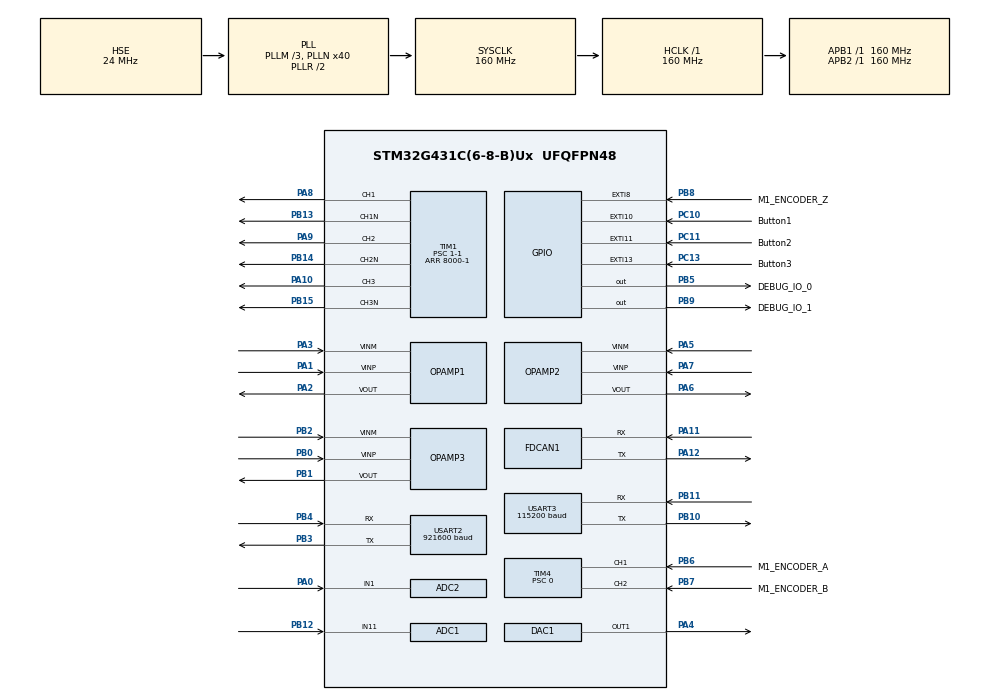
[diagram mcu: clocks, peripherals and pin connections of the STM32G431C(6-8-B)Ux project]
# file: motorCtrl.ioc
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ADC1.Channel-0\#ChannelRegularConversion=ADC_CHANNEL_11
ADC1.ClockPrescaler=ADC_CLOCK_ASYNC_DIV4
ADC1.EnableInjectedConversion=ENABLE
ADC1.ExternalTrigInjecConv=ADC_EXTERNALTRIGINJEC_T1_CC4
ADC1.InjNumberOfConversion=2
ADC1.InjectedChannel-3\#ChannelInjectedConversion=ADC_CHANNEL_3
ADC1.InjectedChannel-4\#ChannelInjectedConversion=ADC_CHANNEL_12
ADC1.InjectedOffsetNumber-3\#ChannelInjectedConversion=ADC_OFFSET_NONE
ADC1.InjectedOffsetNumber-4\#ChannelInjectedConversion=ADC_OFFSET_NONE
ADC1.InjectedRank-3\#ChannelInjectedConversion=1
ADC1.InjectedRank-4\#ChannelInjectedConversion=2
ADC1.InjectedSamplingTime-3\#ChannelInjectedConversion=ADC_SAMPLETIME_6CYCLES_5
ADC1.InjectedSamplingTime-4\#ChannelInjectedConversion=ADC_SAMPLETIME_6CYCLES_5
ADC1.NbrOfConversionFlag=1
ADC1.OffsetNumber-0\#ChannelRegularConversion=ADC_OFFSET_NONE
ADC1.Rank-0\#ChannelRegularConversion=1
ADC1.Rank1_Channel=ADC_CHANNEL_3
ADC1.Rank2_Channel=ADC_CHANNEL_12
ADC1.SamplingTime-0\#ChannelRegularConversion=ADC_SAMPLETIME_2CYCLES_5
ADC1.master=1
ADC2.Channel-2\#ChannelRegularConversion=ADC_CHANNEL_1
ADC2.ClockPrescaler=ADC_CLOCK_ASYNC_DIV4
ADC2.EnableInjectedConversion=ENABLE
ADC2.ExternalTrigInjecConv=ADC_EXTERNALTRIGINJEC_T1_CC4
ADC2.InjNumberOfConversion=1
ADC2.InjectedChannel-3\#ChannelInjectedConversion=ADC_CHANNEL_3
ADC2.InjectedOffsetNumber-3\#ChannelInjectedConversion=ADC_OFFSET_NONE
ADC2.InjectedRank-3\#ChannelInjectedConversion=1
ADC2.InjectedSamplingTime-3\#ChannelInjectedConversion=ADC_SAMPLETIME_6CYCLES_5
ADC2.NbrOfConversionFlag=1
ADC2.OffsetNumber-2\#ChannelRegularConversion=ADC_OFFSET_NONE
ADC2.Rank-2\#ChannelRegularConversion=1
ADC2.SamplingTime-2\#ChannelRegularConversion=ADC_SAMPLETIME_2CYCLES_5
COMP1.TriggerMode=COMP_TRIGGERMODE_IT_RISING
Dma.ADC1.2.Direction=DMA_PERIPH_TO_MEMORY
Dma.ADC1.2.EventEnable=DISABLE
Dma.ADC1.2.Instance=DMA1_Channel3
Dma.ADC1.2.MemDataAlignment=DMA_MDATAALIGN_HALFWORD
Dma.ADC1.2.MemInc=DMA_MINC_ENABLE
Dma.ADC1.2.Mode=DMA_NORMAL
Dma.ADC1.2.PeriphDataAlignment=DMA_PDATAALIGN_HALFWORD
Dma.ADC1.2.PeriphInc=DMA_PINC_DISABLE
Dma.ADC1.2.Polarity=HAL_DMAMUX_REQ_GEN_RISING
Dma.ADC1.2.Priority=DMA_PRIORITY_LOW
Dma.ADC1.2.RequestNumber=1
Dma.ADC1.2.SignalID=NONE
Dma.ADC1.2.SyncEnable=DISABLE
Dma.ADC1.2.SyncPolarity=HAL_DMAMUX_SYNC_NO_EVENT
Dma.ADC1.2.SyncRequestNumber=1
Dma.ADC1.2.SyncSignalID=NONE
Dma.ADC2.3.Direction=DMA_PERIPH_TO_MEMORY
Dma.ADC2.3.EventEnable=DISABLE
Dma.ADC2.3.Instance=DMA1_Channel4
Dma.ADC2.3.MemDataAlignment=DMA_MDATAALIGN_HALFWORD
Dma.ADC2.3.MemInc=DMA_MINC_ENABLE
Dma.ADC2.3.Mode=DMA_NORMAL
Dma.ADC2.3.PeriphDataAlignment=DMA_PDATAALIGN_HALFWORD
Dma.ADC2.3.PeriphInc=DMA_PINC_DISABLE
Dma.ADC2.3.Polarity=HAL_DMAMUX_REQ_GEN_RISING
Dma.ADC2.3.Priority=DMA_PRIORITY_LOW
Dma.ADC2.3.RequestNumber=1
Dma.ADC2.3.SignalID=NONE
Dma.ADC2.3.SyncEnable=DISABLE
Dma.ADC2.3.SyncPolarity=HAL_DMAMUX_SYNC_NO_EVENT
Dma.ADC2.3.SyncRequestNumber=1
Dma.ADC2.3.SyncSignalID=NONE
Dma.Request0=USART3_TX
Dma.Request1=USART2_TX
Dma.Request2=ADC1
Dma.Request3=ADC2
Dma.USART2_TX.1.Direction=DMA_MEMORY_TO_PERIPH
Dma.USART2_TX.1.EventEnable=DISABLE
Dma.USART2_TX.1.Instance=DMA1_Channel2
Dma.USART2_TX.1.MemDataAlignment=DMA_MDATAALIGN_BYTE
Dma.USART2_TX.1.MemInc=DMA_MINC_ENABLE
Dma.USART2_TX.1.Mode=DMA_NORMAL
Dma.USART2_TX.1.PeriphDataAlignment=DMA_PDATAALIGN_BYTE
Dma.USART2_TX.1.PeriphInc=DMA_PINC_DISABLE
Dma.USART2_TX.1.Polarity=HAL_DMAMUX_REQ_GEN_RISING
Dma.USART2_TX.1.Priority=DMA_PRIORITY_LOW
Dma.USART2_TX.1.RequestNumber=1
Dma.USART2_TX.1.SignalID=NONE
Dma.USART2_TX.1.SyncEnable=DISABLE
Dma.USART2_TX.1.SyncPolarity=HAL_DMAMUX_SYNC_NO_EVENT
Dma.USART2_TX.1.SyncRequestNumber=1
Dma.USART2_TX.1.SyncSignalID=NONE
Dma.USART3_TX.0.Direction=DMA_MEMORY_TO_PERIPH
Dma.USART3_TX.0.EventEnable=DISABLE
Dma.USART3_TX.0.Instance=DMA1_Channel1
Dma.USART3_TX.0.MemDataAlignment=DMA_MDATAALIGN_BYTE
Dma.USART3_TX.0.MemInc=DMA_MINC_ENABLE
Dma.USART3_TX.0.Mode=DMA_NORMAL
Dma.USART3_TX.0.PeriphDataAlignment=DMA_PDATAALIGN_BYTE
Dma.USART3_TX.0.PeriphInc=DMA_PINC_DISABLE
Dma.USART3_TX.0.Polarity=HAL_DMAMUX_REQ_GEN_RISING
Dma.USART3_TX.0.Priority=DMA_PRIORITY_LOW
Dma.USART3_TX.0.RequestNumber=1
Dma.USART3_TX.0.SignalID=NONE
Dma.USART3_TX.0.SyncEnable=DISABLE
Dma.USART3_TX.0.SyncPolarity=HAL_DMAMUX_SYNC_NO_EVENT
Dma.USART3_TX.0.SyncRequestNumber=1
Dma.USART3_TX.0.SyncSignalID=NONE
FDCAN1.DataPrescaler=20
FDCAN1.DataTimeSeg1=10
FDCAN1.DataTimeSeg2=5
FDCAN1.ExtFiltersNbr=1
FDCAN1.NominalPrescaler=20
FDCAN1.NominalTimeSeg1=10
FDCAN1.NominalTimeSeg2=5
FDCAN1.StdFiltersNbr=1
Mcu.Family=STM32G4
Mcu.Name=STM32G431C(6-8-B)Ux
Mcu.Package=UFQFPN48
NVIC.ADC1_2_IRQn=true\:0\:0\:false\:false\:true\:true\:true\:true
NVIC.COMP1_2_3_IRQn=true\:0\:0\:false\:false\:true\:false\:true\:true
NVIC.DMA1_Channel1_IRQn=true\:0\:0\:false\:false\:true\:false\:true\:true
NVIC.DMA1_Channel2_IRQn=true\:0\:0\:false\:false\:true\:false\:true\:true
NVIC.DMA1_Channel3_IRQn=true\:0\:0\:false\:false\:true\:false\:true\:true
NVIC.DMA1_Channel4_IRQn=true\:0\:0\:false\:false\:true\:false\:true\:true
NVIC.EXTI15_10_IRQn=true\:2\:0\:true\:false\:true\:true\:true\:true
NVIC.EXTI9_5_IRQn=true\:2\:0\:true\:false\:true\:true\:true\:true
NVIC.FDCAN1_IT0_IRQn=true\:4\:0\:true\:false\:true\:true\:true\:true
NVIC.PriorityGroup=NVIC_PRIORITYGROUP_4
NVIC.TIM1_BRK_TIM15_IRQn=true\:1\:0\:true\:false\:true\:true\:true\:true
NVIC.TIM1_CC_IRQn=true\:1\:0\:true\:false\:true\:true\:true\:true
NVIC.TIM1_UP_TIM16_IRQn=true\:1\:0\:true\:false\:true\:true\:true\:true
NVIC.TIM4_IRQn=true\:4\:0\:true\:false\:true\:true\:true\:true
NVIC.USART2_IRQn=true\:4\:0\:true\:false\:true\:true\:true\:true
NVIC.USART3_IRQn=true\:4\:0\:true\:false\:true\:true\:true\:true
PA0.Mode=IN1-Single-Ended
PA0.Signal=ADC2_IN1
PA1.Mode=Standalone
PA1.Signal=OPAMP1_VINP
PA10.Signal=S_TIM1_CH3
PA11.Mode=FDCAN_Activate
PA11.Signal=FDCAN1_RX
PA12.Mode=FDCAN_Activate
PA12.Signal=FDCAN1_TX
PA13.Mode=Serial_Wire
PA13.Signal=SYS_JTMS-SWDIO
PA14.Mode=Serial_Wire
PA14.Signal=SYS_JTCK-SWCLK
PA2.Signal=SharedAnalog_PA2
PA3.Mode=Standalone
PA3.Signal=OPAMP1_VINM
PA4.Signal=COMP_DAC11_group
PA5.Mode=Standalone
PA5.Signal=OPAMP2_VINM
PA6.Signal=SharedAnalog_PA6
PA7.Mode=Standalone
PA7.Signal=OPAMP2_VINP
PA8.Signal=S_TIM1_CH1
PA9.Signal=S_TIM1_CH2
PB0.Mode=Standalone
PB0.Signal=OPAMP3_VINP
PB1.Signal=SharedAnalog_PB1
PB10.Mode=Asynchronous
PB10.Signal=USART3_TX
PB11.Mode=Asynchronous
PB11.Signal=USART3_RX
PB12.Mode=IN11-Single-Ended
PB12.Signal=ADC1_IN11
PB13.Mode=PWM Generation1 CH1 CH1N
PB13.Signal=TIM1_CH1N
PB14.Mode=PWM Generation2 CH2 CH2N
PB14.Signal=TIM1_CH2N
PB15.Mode=PWM Generation3 CH3 CH3N
PB15.Signal=TIM1_CH3N
PB2.Mode=Standalone
PB2.Signal=OPAMP3_VINM
PB3.Mode=Asynchronous
PB3.Signal=USART2_TX
PB4.Mode=Asynchronous
PB4.Signal=USART2_RX
PB5.GPIO_Label=DEBUG_IO_0
PB5.Signal=GPIO_Output
PB6.GPIO_FM6=SYSCFG_FASTMODEPLUS_PB6
PB6.GPIO_Label=M1_ENCODER_A
PB6.Signal=S_TIM4_CH1
PB7.GPIO_FM7=SYSCFG_FASTMODEPLUS_PB7
PB7.GPIO_Label=M1_ENCODER_B
PB7.Signal=S_TIM4_CH2
PB8-BOOT0.GPIO_Label=M1_ENCODER_Z
PB8-BOOT0.Signal=GPXTI8
PB9.GPIO_Label=DEBUG_IO_1
PB9.Signal=GPIO_Output
PC10.GPIO_Label=Button1
PC10.Signal=GPXTI10
PC11.GPIO_Label=Button2
PC11.Signal=GPXTI11
PC13.GPIO_Label=Button3
PC13.Signal=GPXTI13
PF0-OSC_IN.Mode=HSE-External-Oscillator
PF0-OSC_IN.Signal=RCC_OSC_IN
PF1-OSC_OUT.Mode=HSE-External-Oscillator
PF1-OSC_OUT.Signal=RCC_OSC_OUT
ProjectManager.HeapSize=0x200
ProjectManager.StackSize=0x400
ProjectManager.TargetToolchain=STM32CubeIDE
RCC.ADC12Freq_Value=160000000
RCC.AHBFreq_Value=160000000
RCC.APB1Freq_Value=160000000
RCC.APB1TimFreq_Value=160000000
RCC.APB2Freq_Value=160000000
RCC.APB2TimFreq_Value=160000000
RCC.CortexFreq_Value=160000000
RCC.EXTERNAL_CLOCK_VALUE=12288000
RCC.HCLKFreq_Value=160000000
RCC.HSE_VALUE=24000000
RCC.HSI48_VALUE=48000000
RCC.HSI_VALUE=16000000
RCC.LSE_VALUE=32768
RCC.PLLM=RCC_PLLM_DIV3
RCC.PLLN=40
RCC.PLLSourceVirtual=RCC_PLLSOURCE_HSE
RCC.SYSCLKFreq_VALUE=160000000
RCC.SYSCLKSource=RCC_SYSCLKSOURCE_PLLCLK
RCC.USBFreq_Value=160000000
RCC.VCOOutputFreq_Value=320000000
SH.COMP_DAC11_group.0=DAC1_OUT1,DAC_OUT1
SH.S_TIM1_CH1.0=TIM1_CH1,PWM Generation1 CH1 CH1N
SH.S_TIM1_CH2.0=TIM1_CH2,PWM Generation2 CH2 CH2N
SH.S_TIM1_CH3.0=TIM1_CH3,PWM Generation3 CH3 CH3N
SH.S_TIM4_CH1.0=TIM4_CH1,Encoder_Interface
SH.S_TIM4_CH2.0=TIM4_CH2,Encoder_Interface
SH.SharedAnalog_PA2.0=OPAMP1_VOUT,Standalone
SH.SharedAnalog_PA2.1=ADC1_IN3,IN3-Single-Ended
SH.SharedAnalog_PA6.0=OPAMP2_VOUT,Standalone
SH.SharedAnalog_PA6.1=ADC2_IN3,IN3-Single-Ended
SH.SharedAnalog_PB1.0=OPAMP3_VOUT,Standalone
SH.SharedAnalog_PB1.1=ADC1_IN12,IN12-Single-Ended
SH.SharedAnalog_PB1.2=COMP1_INP,INP
STMicroelectronics.X-CUBE-ALGOBUILD.1.3.0.LibraryCcDSPOoLibraryJjDSPOoLibrary=true
TIM1.BreakFilter=2
TIM1.BreakState=TIM_BREAK_ENABLE
TIM1.Channel-PWM\ Generation1\ CH1\ CH1N=TIM_CHANNEL_1
TIM1.Channel-PWM\ Generation2\ CH2\ CH2N=TIM_CHANNEL_2
TIM1.Channel-PWM\ Generation3\ CH3\ CH3N=TIM_CHANNEL_3
TIM1.Channel-PWM\ Generation4\ No\ Output=TIM_CHANNEL_4
TIM1.ClockDivision=TIM_CLOCKDIVISION_DIV2
TIM1.CounterMode=TIM_COUNTERMODE_CENTERALIGNED1
TIM1.DeadTime=120
TIM1.OCMode_PWM-PWM\ Generation4\ No\ Output=TIM_OCMODE_PWM2
TIM1.PeriodNoDither=8000-1
TIM1.Prescaler=1-1
TIM1.PulseNoDither_4=8000-2
TIM1.RepetitionCounter=1
TIM1.SourceBRKCOMP1=TIM_BREAKINPUTSOURCE_ENABLE
TIM1.TIM_MasterOutputTrigger=TIM_TRGO_OC4REF
TIM4.EncoderMode=TIM_ENCODERMODE_TI12
TIM4.IC1Filter=12
TIM4.IC2Filter=12
TIM4.PeriodNoDither=(4 * (5120)) - 1
TIM4.Prescaler=0
USART2.BaudRate=921600
USART2.VirtualMode-Asynchronous=VM_ASYNC
USART3.BaudRate=115200
USART3.VirtualMode-Asynchronous=VM_ASYNC
VP_COMP1_VS_DAC3OUT1.Mode=INM_DAC3OUT1
VP_CORDIC_VS_CORDIC.Mode=CORDIC_Activate
VP_DAC3_VS_DACI1.Mode=DAC_OUT1_Int
VP_STMicroelectronics.X-CUBE-ALGOBUILD_VS_DSPOoLibraryJjLibrary_1.3.0_1.3.0.Mode=DSPOoLibraryJjLibrary
VP_SYS_VS_DBSignals.Mode=DisableDeadBatterySignals
VP_TIM1_VS_ClockSourceINT.Mode=Internal
VP_TIM1_VS_no_output4.Mode=PWM Generation4 No Output
board=custom

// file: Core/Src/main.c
/* USER CODE BEGIN Header */
/**
  ******************************************************************************
  * @file           : main.c
  * @brief          : Main program body
  ******************************************************************************
  * @attention
  *
  * <h2><center>&copy; Copyright (c) 2025 STMicroelectronics.
  * All rights reserved.</center></h2>
  *
  * This software component is licensed by ST under Ultimate Liberty license
  * SLA0044, the "License"; You may not use this file except in compliance with
  * the License. You may obtain a copy of the License at:
  *                             www.st.com/SLA0044
  *
  ******************************************************************************
  */
/* USER CODE END Header */
#include "main.h"

/* USER CODE BEGIN Includes */
#include <stdio.h>
#include "app_main.h"

#include "easy_mc.h"
/* USER CODE END Includes */

ADC_HandleTypeDef hadc1;
ADC_HandleTypeDef hadc2;
DMA_HandleTypeDef hdma_adc1;
DMA_HandleTypeDef hdma_adc2;

COMP_HandleTypeDef hcomp1;

CORDIC_HandleTypeDef hcordic;

DAC_HandleTypeDef hdac1;
DAC_HandleTypeDef hdac3;

FDCAN_HandleTypeDef hfdcan1;

OPAMP_HandleTypeDef hopamp1;
OPAMP_HandleTypeDef hopamp2;
OPAMP_HandleTypeDef hopamp3;

TIM_HandleTypeDef htim1;
TIM_HandleTypeDef htim4;

UART_HandleTypeDef huart2;
UART_HandleTypeDef huart3;
DMA_HandleTypeDef hdma_usart2_tx;
DMA_HandleTypeDef hdma_usart3_tx;

void SystemClock_Config(void);
static void MX_GPIO_Init(void);
static void MX_DMA_Init(void);
static void MX_USART3_UART_Init(void);
static void MX_ADC1_Init(void);
static void MX_ADC2_Init(void);
static void MX_OPAMP1_Init(void);
static void MX_OPAMP2_Init(void);
static void MX_OPAMP3_Init(void);
static void MX_TIM1_Init(void);
static void MX_DAC1_Init(void);
static void MX_FDCAN1_Init(void);
static void MX_TIM4_Init(void);
static void MX_COMP1_Init(void);
static void MX_DAC3_Init(void);
static void MX_USART2_UART_Init(void);
static void MX_CORDIC_Init(void);

/* USER CODE BEGIN 0 */
#ifdef __GNUC__
#define PUTCHAR_PROTOTYPE int __io_putchar(int ch)
#else
#define PUTCHAR_PROTOTYPE int fputc(int ch, FILE *f)
#endif

PUTCHAR_PROTOTYPE
{
    HAL_UART_Transmit(&huart3, (uint8_t *)&ch, 1, HAL_MAX_DELAY);
    // SEGGER_RTT_Write(0, &ch, 1);
    return ch;
}
/* USER CODE END 0 */

int main(void)
{

  /* MCU Configuration--------------------------------------------------------*/

  /* Reset of all peripherals, Initializes the Flash interface and the Systick. */
  HAL_Init();

  /* Configure the system clock */
  SystemClock_Config();

  /* Initialize all configured peripherals */
  MX_GPIO_Init();
  MX_DMA_Init();
  MX_USART3_UART_Init();
  MX_ADC1_Init();
  MX_ADC2_Init();
  MX_OPAMP1_Init();
  MX_OPAMP2_Init();
  MX_OPAMP3_Init();
  MX_TIM1_Init();
  MX_DAC1_Init();
  MX_FDCAN1_Init();
  MX_TIM4_Init();
  MX_COMP1_Init();
  MX_DAC3_Init();
  MX_USART2_UART_Init();
  MX_CORDIC_Init();
  /* USER CODE BEGIN 2 */
  app_main();

  /* USER CODE END 2 */

  /* Infinite loop */
  /* USER CODE BEGIN WHILE */
  while (1)
  {
    app_main_loop();
    /* USER CODE END WHILE */

  }
}

void SystemClock_Config(void)
{
  RCC_OscInitTypeDef RCC_OscInitStruct = {0};
  RCC_ClkInitTypeDef RCC_ClkInitStruct = {0};
  RCC_PeriphCLKInitTypeDef PeriphClkInit = {0};

  /** Configure the main internal regulator output voltage
  */
  HAL_PWREx_ControlVoltageScaling(PWR_REGULATOR_VOLTAGE_SCALE1_BOOST);
  /** Initializes the RCC Oscillators according to the specified parameters
  * in the RCC_OscInitTypeDef structure.
  */
  RCC_OscInitStruct.OscillatorType = RCC_OSCILLATORTYPE_HSE;
  RCC_OscInitStruct.HSEState = RCC_HSE_ON;
  RCC_OscInitStruct.PLL.PLLState = RCC_PLL_ON;
  RCC_OscInitStruct.PLL.PLLSource = RCC_PLLSOURCE_HSE;
  RCC_OscInitStruct.PLL.PLLM = RCC_PLLM_DIV3;
  RCC_OscInitStruct.PLL.PLLN = 40;
  RCC_OscInitStruct.PLL.PLLP = RCC_PLLP_DIV2;
  RCC_OscInitStruct.PLL.PLLQ = RCC_PLLQ_DIV2;
  RCC_OscInitStruct.PLL.PLLR = RCC_PLLR_DIV2;
  if (HAL_RCC_OscConfig(&RCC_OscInitStruct) != HAL_OK)
  {
    Error_Handler();
  }
  /** Initializes the CPU, AHB and APB buses clocks
  */
  RCC_ClkInitStruct.ClockType = RCC_CLOCKTYPE_HCLK|RCC_CLOCKTYPE_SYSCLK
                              |RCC_CLOCKTYPE_PCLK1|RCC_CLOCKTYPE_PCLK2;
  RCC_ClkInitStruct.SYSCLKSource = RCC_SYSCLKSOURCE_PLLCLK;
  RCC_ClkInitStruct.AHBCLKDivider = RCC_SYSCLK_DIV1;
  RCC_ClkInitStruct.APB1CLKDivider = RCC_HCLK_DIV1;
  RCC_ClkInitStruct.APB2CLKDivider = RCC_HCLK_DIV1;

  if (HAL_RCC_ClockConfig(&RCC_ClkInitStruct, FLASH_LATENCY_4) != HAL_OK)
  {
    Error_Handler();
  }
  /** Initializes the peripherals clocks
  */
  PeriphClkInit.PeriphClockSelection = RCC_PERIPHCLK_USART2|RCC_PERIPHCLK_USART3
                              |RCC_PERIPHCLK_ADC12|RCC_PERIPHCLK_FDCAN;
  PeriphClkInit.Usart2ClockSelection = RCC_USART2CLKSOURCE_PCLK1;
  PeriphClkInit.Usart3ClockSelection = RCC_USART3CLKSOURCE_PCLK1;
  PeriphClkInit.FdcanClockSelection = RCC_FDCANCLKSOURCE_PCLK1;
  PeriphClkInit.Adc12ClockSelection = RCC_ADC12CLKSOURCE_SYSCLK;
  if (HAL_RCCEx_PeriphCLKConfig(&PeriphClkInit) != HAL_OK)
  {
    Error_Handler();
  }
}

static void MX_ADC1_Init(void)
{

  ADC_MultiModeTypeDef multimode = {0};
  ADC_ChannelConfTypeDef sConfig = {0};
  ADC_InjectionConfTypeDef sConfigInjected = {0};

  /** Common config
  */
  hadc1.Instance = ADC1;
  hadc1.Init.ClockPrescaler = ADC_CLOCK_ASYNC_DIV4;
  hadc1.Init.Resolution = ADC_RESOLUTION_12B;
  hadc1.Init.DataAlign = ADC_DATAALIGN_RIGHT;
  hadc1.Init.GainCompensation = 0;
  hadc1.Init.ScanConvMode = ADC_SCAN_ENABLE;
  hadc1.Init.EOCSelection = ADC_EOC_SINGLE_CONV;
  hadc1.Init.LowPowerAutoWait = DISABLE;
  hadc1.Init.ContinuousConvMode = DISABLE;
  hadc1.Init.NbrOfConversion = 1;
  hadc1.Init.DiscontinuousConvMode = DISABLE;
  hadc1.Init.ExternalTrigConv = ADC_SOFTWARE_START;
  hadc1.Init.ExternalTrigConvEdge = ADC_EXTERNALTRIGCONVEDGE_NONE;
  hadc1.Init.DMAContinuousRequests = DISABLE;
  hadc1.Init.Overrun = ADC_OVR_DATA_PRESERVED;
  hadc1.Init.OversamplingMode = DISABLE;
  if (HAL_ADC_Init(&hadc1) != HAL_OK)
  {
    Error_Handler();
  }
  /** Configure the ADC multi-mode
  */
  multimode.Mode = ADC_MODE_INDEPENDENT;
  if (HAL_ADCEx_MultiModeConfigChannel(&hadc1, &multimode) != HAL_OK)
  {
    Error_Handler();
  }
  /** Configure Regular Channel
  */
  sConfig.Channel = ADC_CHANNEL_11;
  sConfig.Rank = ADC_REGULAR_RANK_1;
  sConfig.SamplingTime = ADC_SAMPLETIME_2CYCLES_5;
  sConfig.SingleDiff = ADC_SINGLE_ENDED;
  sConfig.OffsetNumber = ADC_OFFSET_NONE;
  sConfig.Offset = 0;
  if (HAL_ADC_ConfigChannel(&hadc1, &sConfig) != HAL_OK)
  {
    Error_Handler();
  }
  /** Configure Injected Channel
  */
  sConfigInjected.InjectedChannel = ADC_CHANNEL_3;
  sConfigInjected.InjectedRank = ADC_INJECTED_RANK_1;
  sConfigInjected.InjectedSamplingTime = ADC_SAMPLETIME_6CYCLES_5;
  sConfigInjected.InjectedSingleDiff = ADC_SINGLE_ENDED;
  sConfigInjected.InjectedOffsetNumber = ADC_OFFSET_NONE;
  sConfigInjected.InjectedOffset = 0;
  sConfigInjected.InjectedNbrOfConversion = 2;
  sConfigInjected.InjectedDiscontinuousConvMode = DISABLE;
  sConfigInjected.AutoInjectedConv = DISABLE;
  sConfigInjected.QueueInjectedContext = DISABLE;
  sConfigInjected.ExternalTrigInjecConv = ADC_EXTERNALTRIGINJEC_T1_CC4;
  sConfigInjected.ExternalTrigInjecConvEdge = ADC_EXTERNALTRIGINJECCONV_EDGE_RISING;
  sConfigInjected.InjecOversamplingMode = DISABLE;
  if (HAL_ADCEx_InjectedConfigChannel(&hadc1, &sConfigInjected) != HAL_OK)
  {
    Error_Handler();
  }
  /** Configure Injected Channel
  */
  sConfigInjected.InjectedChannel = ADC_CHANNEL_12;
  sConfigInjected.InjectedRank = ADC_INJECTED_RANK_2;
  if (HAL_ADCEx_InjectedConfigChannel(&hadc1, &sConfigInjected) != HAL_OK)
  {
    Error_Handler();
  }

}

static void MX_ADC2_Init(void)
{

  ADC_ChannelConfTypeDef sConfig = {0};
  ADC_InjectionConfTypeDef sConfigInjected = {0};

  /** Common config
  */
  hadc2.Instance = ADC2;
  hadc2.Init.ClockPrescaler = ADC_CLOCK_ASYNC_DIV4;
  hadc2.Init.Resolution = ADC_RESOLUTION_12B;
  hadc2.Init.DataAlign = ADC_DATAALIGN_RIGHT;
  hadc2.Init.GainCompensation = 0;
  hadc2.Init.ScanConvMode = ADC_SCAN_DISABLE;
  hadc2.Init.EOCSelection = ADC_EOC_SINGLE_CONV;
  hadc2.Init.LowPowerAutoWait = DISABLE;
  hadc2.Init.ContinuousConvMode = DISABLE;
  hadc2.Init.NbrOfConversion = 1;
  hadc2.Init.DiscontinuousConvMode = DISABLE;
  hadc2.Init.ExternalTrigConv = ADC_SOFTWARE_START;
  hadc2.Init.ExternalTrigConvEdge = ADC_EXTERNALTRIGCONVEDGE_NONE;
  hadc2.Init.DMAContinuousRequests = DISABLE;
  hadc2.Init.Overrun = ADC_OVR_DATA_PRESERVED;
  hadc2.Init.OversamplingMode = DISABLE;
  if (HAL_ADC_Init(&hadc2) != HAL_OK)
  {
    Error_Handler();
  }
  /** Configure Regular Channel
  */
  sConfig.Channel = ADC_CHANNEL_1;
  sConfig.Rank = ADC_REGULAR_RANK_1;
  sConfig.SamplingTime = ADC_SAMPLETIME_2CYCLES_5;
  sConfig.SingleDiff = ADC_SINGLE_ENDED;
  sConfig.OffsetNumber = ADC_OFFSET_NONE;
  sConfig.Offset = 0;
  if (HAL_ADC_ConfigChannel(&hadc2, &sConfig) != HAL_OK)
  {
    Error_Handler();
  }
  /** Configure Injected Channel
  */
  sConfigInjected.InjectedChannel = ADC_CHANNEL_3;
  sConfigInjected.InjectedRank = ADC_INJECTED_RANK_1;
  sConfigInjected.InjectedSamplingTime = ADC_SAMPLETIME_6CYCLES_5;
  sConfigInjected.InjectedSingleDiff = ADC_SINGLE_ENDED;
  sConfigInjected.InjectedOffsetNumber = ADC_OFFSET_NONE;
  sConfigInjected.InjectedOffset = 0;
  sConfigInjected.InjectedNbrOfConversion = 1;
  sConfigInjected.InjectedDiscontinuousConvMode = DISABLE;
  sConfigInjected.AutoInjectedConv = DISABLE;
  sConfigInjected.QueueInjectedContext = DISABLE;
  sConfigInjected.ExternalTrigInjecConv = ADC_EXTERNALTRIGINJEC_T1_CC4;
  sConfigInjected.ExternalTrigInjecConvEdge = ADC_EXTERNALTRIGINJECCONV_EDGE_RISING;
  sConfigInjected.InjecOversamplingMode = DISABLE;
  if (HAL_ADCEx_InjectedConfigChannel(&hadc2, &sConfigInjected) != HAL_OK)
  {
    Error_Handler();
  }

}

static void MX_COMP1_Init(void)
{

  hcomp1.Instance = COMP1;
  hcomp1.Init.InputPlus = COMP_INPUT_PLUS_IO2;
  hcomp1.Init.InputMinus = COMP_INPUT_MINUS_DAC3_CH1;
  hcomp1.Init.OutputPol = COMP_OUTPUTPOL_NONINVERTED;
  hcomp1.Init.Hysteresis = COMP_HYSTERESIS_NONE;
  hcomp1.Init.BlankingSrce = COMP_BLANKINGSRC_NONE;
  hcomp1.Init.TriggerMode = COMP_TRIGGERMODE_IT_RISING;
  if (HAL_COMP_Init(&hcomp1) != HAL_OK)
  {
    Error_Handler();
  }

}

static void MX_CORDIC_Init(void)
{

  hcordic.Instance = CORDIC;
  if (HAL_CORDIC_Init(&hcordic) != HAL_OK)
  {
    Error_Handler();
  }

}

static void MX_DAC1_Init(void)
{

  DAC_ChannelConfTypeDef sConfig = {0};

  /** DAC Initialization
  */
  hdac1.Instance = DAC1;
  if (HAL_DAC_Init(&hdac1) != HAL_OK)
  {
    Error_Handler();
  }
  /** DAC channel OUT1 config
  */
  sConfig.DAC_HighFrequency = DAC_HIGH_FREQUENCY_INTERFACE_MODE_AUTOMATIC;
  sConfig.DAC_DMADoubleDataMode = DISABLE;
  sConfig.DAC_SignedFormat = DISABLE;
  sConfig.DAC_SampleAndHold = DAC_SAMPLEANDHOLD_DISABLE;
  sConfig.DAC_Trigger = DAC_TRIGGER_NONE;
  sConfig.DAC_Trigger2 = DAC_TRIGGER_NONE;
  sConfig.DAC_OutputBuffer = DAC_OUTPUTBUFFER_ENABLE;
  sConfig.DAC_ConnectOnChipPeripheral = DAC_CHIPCONNECT_EXTERNAL;
  sConfig.DAC_UserTrimming = DAC_TRIMMING_FACTORY;
  if (HAL_DAC_ConfigChannel(&hdac1, &sConfig, DAC_CHANNEL_1) != HAL_OK)
  {
    Error_Handler();
  }

}

static void MX_DAC3_Init(void)
{

  DAC_ChannelConfTypeDef sConfig = {0};

  /** DAC Initialization
  */
  hdac3.Instance = DAC3;
  if (HAL_DAC_Init(&hdac3) != HAL_OK)
  {
    Error_Handler();
  }
  /** DAC channel OUT1 config
  */
  sConfig.DAC_HighFrequency = DAC_HIGH_FREQUENCY_INTERFACE_MODE_AUTOMATIC;
  sConfig.DAC_DMADoubleDataMode = DISABLE;
  sConfig.DAC_SignedFormat = DISABLE;
  sConfig.DAC_SampleAndHold = DAC_SAMPLEANDHOLD_DISABLE;
  sConfig.DAC_Trigger = DAC_TRIGGER_NONE;
  sConfig.DAC_Trigger2 = DAC_TRIGGER_NONE;
  sConfig.DAC_OutputBuffer = DAC_OUTPUTBUFFER_DISABLE;
  sConfig.DAC_ConnectOnChipPeripheral = DAC_CHIPCONNECT_INTERNAL;
  sConfig.DAC_UserTrimming = DAC_TRIMMING_FACTORY;
  if (HAL_DAC_ConfigChannel(&hdac3, &sConfig, DAC_CHANNEL_1) != HAL_OK)
  {
    Error_Handler();
  }

}

static void MX_FDCAN1_Init(void)
{

  hfdcan1.Instance = FDCAN1;
  hfdcan1.Init.ClockDivider = FDCAN_CLOCK_DIV1;
  hfdcan1.Init.FrameFormat = FDCAN_FRAME_CLASSIC;
  hfdcan1.Init.Mode = FDCAN_MODE_NORMAL;
  hfdcan1.Init.AutoRetransmission = DISABLE;
  hfdcan1.Init.TransmitPause = DISABLE;
  hfdcan1.Init.ProtocolException = DISABLE;
  hfdcan1.Init.NominalPrescaler = 20;
  hfdcan1.Init.NominalSyncJumpWidth = 1;
  hfdcan1.Init.NominalTimeSeg1 = 10;
  hfdcan1.Init.NominalTimeSeg2 = 5;
  hfdcan1.Init.DataPrescaler = 20;
  hfdcan1.Init.DataSyncJumpWidth = 1;
  hfdcan1.Init.DataTimeSeg1 = 10;
  hfdcan1.Init.DataTimeSeg2 = 5;
  hfdcan1.Init.StdFiltersNbr = 1;
  hfdcan1.Init.ExtFiltersNbr = 1;
  hfdcan1.Init.TxFifoQueueMode = FDCAN_TX_FIFO_OPERATION;
  if (HAL_FDCAN_Init(&hfdcan1) != HAL_OK)
  {
    Error_Handler();
  }

}

static void MX_OPAMP1_Init(void)
{

  hopamp1.Instance = OPAMP1;
  hopamp1.Init.PowerMode = OPAMP_POWERMODE_NORMALSPEED;
  hopamp1.Init.Mode = OPAMP_STANDALONE_MODE;
  hopamp1.Init.InvertingInput = OPAMP_INVERTINGINPUT_IO0;
  hopamp1.Init.NonInvertingInput = OPAMP_NONINVERTINGINPUT_IO0;
  hopamp1.Init.InternalOutput = DISABLE;
  hopamp1.Init.TimerControlledMuxmode = OPAMP_TIMERCONTROLLEDMUXMODE_DISABLE;
  hopamp1.Init.UserTrimming = OPAMP_TRIMMING_FACTORY;
  if (HAL_OPAMP_Init(&hopamp1) != HAL_OK)
  {
    Error_Handler();
  }

}

static void MX_OPAMP2_Init(void)
{

  hopamp2.Instance = OPAMP2;
  hopamp2.Init.PowerMode = OPAMP_POWERMODE_NORMALSPEED;
  hopamp2.Init.Mode = OPAMP_STANDALONE_MODE;
  hopamp2.Init.InvertingInput = OPAMP_INVERTINGINPUT_IO0;
  hopamp2.Init.NonInvertingInput = OPAMP_NONINVERTINGINPUT_IO0;
  hopamp2.Init.InternalOutput = DISABLE;
  hopamp2.Init.TimerControlledMuxmode = OPAMP_TIMERCONTROLLEDMUXMODE_DISABLE;
  hopamp2.Init.UserTrimming = OPAMP_TRIMMING_FACTORY;
  if (HAL_OPAMP_Init(&hopamp2) != HAL_OK)
  {
    Error_Handler();
  }

}

static void MX_OPAMP3_Init(void)
{

  hopamp3.Instance = OPAMP3;
  hopamp3.Init.PowerMode = OPAMP_POWERMODE_NORMALSPEED;
  hopamp3.Init.Mode = OPAMP_STANDALONE_MODE;
  hopamp3.Init.InvertingInput = OPAMP_INVERTINGINPUT_IO0;
  hopamp3.Init.NonInvertingInput = OPAMP_NONINVERTINGINPUT_IO0;
  hopamp3.Init.InternalOutput = DISABLE;
  hopamp3.Init.TimerControlledMuxmode = OPAMP_TIMERCONTROLLEDMUXMODE_DISABLE;
  hopamp3.Init.UserTrimming = OPAMP_TRIMMING_FACTORY;
  if (HAL_OPAMP_Init(&hopamp3) != HAL_OK)
  {
    Error_Handler();
  }

}

static void MX_TIM1_Init(void)
{

  TIM_ClockConfigTypeDef sClockSourceConfig = {0};
  TIM_MasterConfigTypeDef sMasterConfig = {0};
  TIMEx_BreakInputConfigTypeDef sBreakInputConfig = {0};
  TIM_OC_InitTypeDef sConfigOC = {0};
  TIM_BreakDeadTimeConfigTypeDef sBreakDeadTimeConfig = {0};

  htim1.Instance = TIM1;
  htim1.Init.Prescaler = 1-1;
  htim1.Init.CounterMode = TIM_COUNTERMODE_CENTERALIGNED1;
  htim1.Init.Period = EASY_MC_PWM_PERIOD_CYCLES - 1;
  htim1.Init.ClockDivision = TIM_CLOCKDIVISION_DIV2;
  htim1.Init.RepetitionCounter = 1;
  htim1.Init.AutoReloadPreload = TIM_AUTORELOAD_PRELOAD_DISABLE;
  if (HAL_TIM_Base_Init(&htim1) != HAL_OK)
  {
    Error_Handler();
  }
  sClockSourceConfig.ClockSource = TIM_CLOCKSOURCE_INTERNAL;
  if (HAL_TIM_ConfigClockSource(&htim1, &sClockSourceConfig) != HAL_OK)
  {
    Error_Handler();
  }
  if (HAL_TIM_PWM_Init(&htim1) != HAL_OK)
  {
    Error_Handler();
  }
  sMasterConfig.MasterOutputTrigger = TIM_TRGO_OC4REF;
  sMasterConfig.MasterOutputTrigger2 = TIM_TRGO2_RESET;
  sMasterConfig.MasterSlaveMode = TIM_MASTERSLAVEMODE_DISABLE;
  if (HAL_TIMEx_MasterConfigSynchronization(&htim1, &sMasterConfig) != HAL_OK)
  {
    Error_Handler();
  }
  sBreakInputConfig.Source = TIM_BREAKINPUTSOURCE_COMP1;
  sBreakInputConfig.Enable = TIM_BREAKINPUTSOURCE_ENABLE;
  sBreakInputConfig.Polarity = TIM_BREAKINPUTSOURCE_POLARITY_HIGH;
  if (HAL_TIMEx_ConfigBreakInput(&htim1, TIM_BREAKINPUT_BRK, &sBreakInputConfig) != HAL_OK)
  {
    Error_Handler();
  }
  sConfigOC.OCMode = TIM_OCMODE_PWM1;
  sConfigOC.Pulse = 0;
  sConfigOC.OCPolarity = TIM_OCPOLARITY_HIGH;
  sConfigOC.OCNPolarity = TIM_OCNPOLARITY_HIGH;
  sConfigOC.OCFastMode = TIM_OCFAST_DISABLE;
  sConfigOC.OCIdleState = TIM_OCIDLESTATE_RESET;
  sConfigOC.OCNIdleState = TIM_OCNIDLESTATE_RESET;
  if (HAL_TIM_PWM_ConfigChannel(&htim1, &sConfigOC, TIM_CHANNEL_1) != HAL_OK)
  {
    Error_Handler();
  }
  if (HAL_TIM_PWM_ConfigChannel(&htim1, &sConfigOC, TIM_CHANNEL_2) != HAL_OK)
  {
    Error_Handler();
  }
  if (HAL_TIM_PWM_ConfigChannel(&htim1, &sConfigOC, TIM_CHANNEL_3) != HAL_OK)
  {
    Error_Handler();
  }
  sConfigOC.OCMode = TIM_OCMODE_PWM2;
  sConfigOC.Pulse = EASY_MC_PWM_PERIOD_CYCLES - 2;
  if (HAL_TIM_PWM_ConfigChannel(&htim1, &sConfigOC, TIM_CHANNEL_4) != HAL_OK)
  {
    Error_Handler();
  }
  sBreakDeadTimeConfig.OffStateRunMode = TIM_OSSR_DISABLE;
  sBreakDeadTimeConfig.OffStateIDLEMode = TIM_OSSI_DISABLE;
  sBreakDeadTimeConfig.LockLevel = TIM_LOCKLEVEL_OFF;
  sBreakDeadTimeConfig.DeadTime = 120;
  sBreakDeadTimeConfig.BreakState = TIM_BREAK_ENABLE;
  sBreakDeadTimeConfig.BreakPolarity = TIM_BREAKPOLARITY_HIGH;
  sBreakDeadTimeConfig.BreakFilter = 2;
  sBreakDeadTimeConfig.BreakAFMode = TIM_BREAK_AFMODE_INPUT;
  sBreakDeadTimeConfig.Break2State = TIM_BREAK2_DISABLE;
  sBreakDeadTimeConfig.Break2Polarity = TIM_BREAK2POLARITY_HIGH;
  sBreakDeadTimeConfig.Break2Filter = 0;
  sBreakDeadTimeConfig.Break2AFMode = TIM_BREAK_AFMODE_INPUT;
  sBreakDeadTimeConfig.AutomaticOutput = TIM_AUTOMATICOUTPUT_DISABLE;
  if (HAL_TIMEx_ConfigBreakDeadTime(&htim1, &sBreakDeadTimeConfig) != HAL_OK)
  {
    Error_Handler();
  }
  HAL_TIM_MspPostInit(&htim1);

}

static void MX_TIM4_Init(void)
{

  TIM_Encoder_InitTypeDef sConfig = {0};
  TIM_MasterConfigTypeDef sMasterConfig = {0};

  htim4.Instance = TIM4;
  htim4.Init.Prescaler = 0;
  htim4.Init.CounterMode = TIM_COUNTERMODE_UP;
  htim4.Init.Period = EASY_MC_PULSE_NBR - 1;
  htim4.Init.ClockDivision = TIM_CLOCKDIVISION_DIV1;
  htim4.Init.AutoReloadPreload = TIM_AUTORELOAD_PRELOAD_DISABLE;
  sConfig.EncoderMode = TIM_ENCODERMODE_TI12;
  sConfig.IC1Polarity = TIM_ICPOLARITY_RISING;
  sConfig.IC1Selection = TIM_ICSELECTION_DIRECTTI;
  sConfig.IC1Prescaler = TIM_ICPSC_DIV1;
  sConfig.IC1Filter = 12;
  sConfig.IC2Polarity = TIM_ICPOLARITY_RISING;
  sConfig.IC2Selection = TIM_ICSELECTION_DIRECTTI;
  sConfig.IC2Prescaler = TIM_ICPSC_DIV1;
  sConfig.IC2Filter = 12;
  if (HAL_TIM_Encoder_Init(&htim4, &sConfig) != HAL_OK)
  {
    Error_Handler();
  }
  sMasterConfig.MasterOutputTrigger = TIM_TRGO_RESET;
  sMasterConfig.MasterSlaveMode = TIM_MASTERSLAVEMODE_DISABLE;
  if (HAL_TIMEx_MasterConfigSynchronization(&htim4, &sMasterConfig) != HAL_OK)
  {
    Error_Handler();
  }

}

static void MX_USART2_UART_Init(void)
{

  huart2.Instance = USART2;
  huart2.Init.BaudRate = 2000000;
  huart2.Init.WordLength = UART_WORDLENGTH_8B;
  huart2.Init.StopBits = UART_STOPBITS_1;
  huart2.Init.Parity = UART_PARITY_NONE;
  huart2.Init.Mode = UART_MODE_TX_RX;
  huart2.Init.HwFlowCtl = UART_HWCONTROL_NONE;
  huart2.Init.OverSampling = UART_OVERSAMPLING_16;
  huart2.Init.OneBitSampling = UART_ONE_BIT_SAMPLE_DISABLE;
  huart2.Init.ClockPrescaler = UART_PRESCALER_DIV1;
  huart2.AdvancedInit.AdvFeatureInit = UART_ADVFEATURE_NO_INIT;
  if (HAL_UART_Init(&huart2) != HAL_OK)
  {
    Error_Handler();
  }
  if (HAL_UARTEx_SetTxFifoThreshold(&huart2, UART_TXFIFO_THRESHOLD_1_8) != HAL_OK)
  {
    Error_Handler();
  }
  if (HAL_UARTEx_SetRxFifoThreshold(&huart2, UART_RXFIFO_THRESHOLD_1_8) != HAL_OK)
  {
    Error_Handler();
  }
  if (HAL_UARTEx_DisableFifoMode(&huart2) != HAL_OK)
  {
    Error_Handler();
  }

}

static void MX_USART3_UART_Init(void)
{

  huart3.Instance = USART3;
  huart3.Init.BaudRate = 115200;
  huart3.Init.WordLength = UART_WORDLENGTH_8B;
  huart3.Init.StopBits = UART_STOPBITS_1;
  huart3.Init.Parity = UART_PARITY_NONE;
  huart3.Init.Mode = UART_MODE_TX_RX;
  huart3.Init.HwFlowCtl = UART_HWCONTROL_NONE;
  huart3.Init.OverSampling = UART_OVERSAMPLING_16;
  huart3.Init.OneBitSampling = UART_ONE_BIT_SAMPLE_DISABLE;
  huart3.Init.ClockPrescaler = UART_PRESCALER_DIV1;
  huart3.AdvancedInit.AdvFeatureInit = UART_ADVFEATURE_NO_INIT;
  if (HAL_UART_Init(&huart3) != HAL_OK)
  {
    Error_Handler();
  }
  if (HAL_UARTEx_SetTxFifoThreshold(&huart3, UART_TXFIFO_THRESHOLD_1_8) != HAL_OK)
  {
    Error_Handler();
  }
  if (HAL_UARTEx_SetRxFifoThreshold(&huart3, UART_RXFIFO_THRESHOLD_1_8) != HAL_OK)
  {
    Error_Handler();
  }
  if (HAL_UARTEx_DisableFifoMode(&huart3) != HAL_OK)
  {
    Error_Handler();
  }

}

static void MX_DMA_Init(void)
{

  /* DMA controller clock enable */
  __HAL_RCC_DMAMUX1_CLK_ENABLE();
  __HAL_RCC_DMA1_CLK_ENABLE();

  /* DMA interrupt init */
  /* DMA1_Channel1_IRQn interrupt configuration */
  HAL_NVIC_SetPriority(DMA1_Channel1_IRQn, 0, 0);
  HAL_NVIC_EnableIRQ(DMA1_Channel1_IRQn);
  /* DMA1_Channel2_IRQn interrupt configuration */
  HAL_NVIC_SetPriority(DMA1_Channel2_IRQn, 0, 0);
  HAL_NVIC_EnableIRQ(DMA1_Channel2_IRQn);
  /* DMA1_Channel3_IRQn interrupt configuration */
  HAL_NVIC_SetPriority(DMA1_Channel3_IRQn, 0, 0);
  HAL_NVIC_EnableIRQ(DMA1_Channel3_IRQn);
  /* DMA1_Channel4_IRQn interrupt configuration */
  HAL_NVIC_SetPriority(DMA1_Channel4_IRQn, 0, 0);
  HAL_NVIC_EnableIRQ(DMA1_Channel4_IRQn);

}

static void MX_GPIO_Init(void)
{
  GPIO_InitTypeDef GPIO_InitStruct = {0};

  /* GPIO Ports Clock Enable */
  __HAL_RCC_GPIOC_CLK_ENABLE();
  __HAL_RCC_GPIOF_CLK_ENABLE();
  __HAL_RCC_GPIOA_CLK_ENABLE();
  __HAL_RCC_GPIOB_CLK_ENABLE();

  /*Configure GPIO pin Output Level */
  HAL_GPIO_WritePin(GPIOB, DEBUG_IO_0_Pin|DEBUG_IO_1_Pin, GPIO_PIN_RESET);

  /*Configure GPIO pins : Button3_Pin Button1_Pin Button2_Pin */
  GPIO_InitStruct.Pin = Button3_Pin|Button1_Pin|Button2_Pin;
  GPIO_InitStruct.Mode = GPIO_MODE_IT_RISING;
  GPIO_InitStruct.Pull = GPIO_NOPULL;
  HAL_GPIO_Init(GPIOC, &GPIO_InitStruct);

  /*Configure GPIO pins : DEBUG_IO_0_Pin DEBUG_IO_1_Pin */
  GPIO_InitStruct.Pin = DEBUG_IO_0_Pin|DEBUG_IO_1_Pin;
  GPIO_InitStruct.Mode = GPIO_MODE_OUTPUT_PP;
  GPIO_InitStruct.Pull = GPIO_NOPULL;
  GPIO_InitStruct.Speed = GPIO_SPEED_FREQ_LOW;
  HAL_GPIO_Init(GPIOB, &GPIO_InitStruct);

  /*Configure GPIO pin : M1_ENCODER_Z_Pin */
  GPIO_InitStruct.Pin = M1_ENCODER_Z_Pin;
  GPIO_InitStruct.Mode = GPIO_MODE_IT_RISING;
  GPIO_InitStruct.Pull = GPIO_NOPULL;
  HAL_GPIO_Init(M1_ENCODER_Z_GPIO_Port, &GPIO_InitStruct);

  /* EXTI interrupt init*/
  HAL_NVIC_SetPriority(EXTI9_5_IRQn, 2, 0);
  HAL_NVIC_EnableIRQ(EXTI9_5_IRQn);

  HAL_NVIC_SetPriority(EXTI15_10_IRQn, 2, 0);
  HAL_NVIC_EnableIRQ(EXTI15_10_IRQn);

}

void Error_Handler(void)
{
  __disable_irq();
  while (1)
  {
  }
}

/************************ (C) COPYRIGHT STMicroelectronics *****END OF FILE****/
